# ATmega644 device description
Architecture: AVR8; Family: megaAVR
Registers are 8-bit, access not given, no defined reset value unless marked. A register's access mark holds for its fields unless they carry their own. Offsets are from the block's base; [hi:lo] are bit positions; {n}, {i} and the like mark numbered series.

## ADC — Analog-to-Digital Converter
Instances: ADC 0x00
0x78 ADC 16-bit — ADC Data Register Bytes
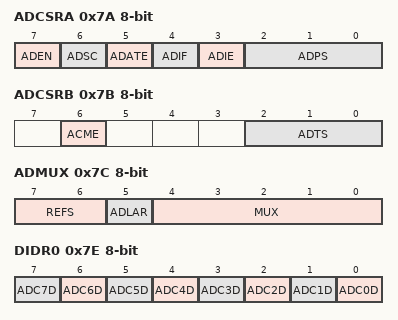
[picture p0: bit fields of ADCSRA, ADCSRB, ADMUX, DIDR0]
0x7A ADCSRA — The ADC Control and Status register A
  [7] ADEN — ADC Enable
  [6] ADSC — ADC Start Conversion
  [5] ADATE — ADC Auto Trigger Enable
  [4] ADIF — ADC Interrupt Flag
  [3] ADIE — ADC Interrupt Enable
  [2:0] ADPS — ADC Prescaler Select Bits
    0=2; 1=2; 2=4; 3=8; 4=16; 5=32; 6=64; 7=128
0x7B ADCSRB — The ADC Control and Status register B
  [6] ACME
  [2:0] ADTS — ADC Auto Trigger Source bits
    0=Free Running mode; 1=Analog Comparator; 2=External Interrupt Request 0; 3=Timer/Counter0 Compare Match A; 4=Timer/Counter0 Overflow; 5=Timer/Counter1 Compare Match B; 6=Timer/Counter1 Overflow; 7=Timer/Counter1 Capture Event
0x7C ADMUX — The ADC multiplexer Selection Register
  [7:6] REFS — Reference Selection Bits
    0=AREF, Internal Vref turned off; 1=AVCC with external capacitor at AREF pin; 2=Internal 1.1V Voltage Reference with external capacitor at AREF pin; 3=Internal 2.56V Voltage Reference with external capacitor at AREF pin
  [5] ADLAR — Left Adjust Result
  [4:0] MUX — Analog Channel and Gain Selection Bits
    {v}=ADC{v} (ADC Single Ended Input pin {v}) (v=0..7); 8=ADC0_ADC0_10X (ADC Differential Inputs Postive pin 0 Negative pin 0 10x Gain); 9=ADC1_ADC0_10X (ADC Differential Inputs Postive pin 1 Negative pin 0 10x Gain); 10=ADC0_ADC0_200x (ADC Differential Inputs Postive pin 0 Negative pin 0 200x Gain); 11=ADC1_ADC0_200X (ADC Differential Inputs Postive pin 1 Negative pin 0 200x Gain); 12=ADC2_ADC2_10X (ADC Differential Inputs Postive pin 2 Negative pin 2 10x Gain); 13=ADC3_ADC2_10X (ADC Differential Inputs Postive pin 3 Negative pin 2 10x Gain); 14=ADC2_ADC2_200X (ADC Differential Inputs Postive pin 2 Negative pin 2 200x Gain); 15=ADC3_ADC2_200X (ADC Differential Inputs Postive pin 3 Negative pin 2 200x Gain); {v}=ADC{v-16}_ADC1_1X (ADC Differential Inputs Postive pin {v-16} Negative pin 1 1x Gain) (v=16..23); {v}=ADC{v-24}_ADC2_1X (ADC Differential Inputs Postive pin {v-24} Negative pin 2 1x Gain) (v=24..29); 30=ADC_VBG (Internal Reference (VBG)); 31=ADC_GND (0V (GND))
0x7E DIDR0 — Digital Input Disable Register
  [n] ADC{n}D (n=0..7)

## TC1 (TC16 module) — Timer/Counter, 16-bit
Instances: TC1 0x00
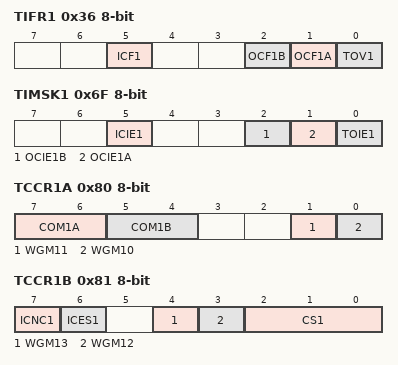
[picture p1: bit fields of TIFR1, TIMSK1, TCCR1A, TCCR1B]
0x36 TIFR1 — Timer/Counter Interrupt Flag register
  [5] ICF1 — Timer/Counter1 Input Capture Flag
  [2] OCF1B — Timer/Counter1 Output Compare B Match Flag
  [1] OCF1A — Timer/Counter1 Output Compare A Match Flag
  [0] TOV1 — Timer/Counter1 Overflow Flag
0x6F TIMSK1 — Timer/Counter1 Interrupt Mask Register
  [5] ICIE1 — Timer/Counter1 Input Capture Interrupt Enable
  [2] OCIE1B — Timer/Counter1 Output Compare B Match Interrupt Enable
  [1] OCIE1A — Timer/Counter1 Output Compare A Match Interrupt Enable
  [0] TOIE1 — Timer/Counter1 Overflow Interrupt Enable
0x80 TCCR1A — Timer/Counter1 Control Register A
  [7:6] COM1A — Compare Output Mode 1A, bits
  [5:4] COM1B — Compare Output Mode 1B, bits
  [1] WGM11 — Waveform Generation Mode
  [0] WGM10 — Waveform Generation Mode
0x81 TCCR1B — Timer/Counter1 Control Register B
  [7] ICNC1 — Input Capture 1 Noise Canceler
  [6] ICES1 — Input Capture 1 Edge Select
  [4] WGM13 (bit 2 of the value upward) — Waveform Generation Mode
  [3] WGM12 (bit 2 of the value upward) — Waveform Generation Mode
  [2:0] CS1 — Clock Select1 bits
    0=No Clock Source (Stopped); 1=Running, No Prescaling; 2=Running, CLK/8; 3=Running, CLK/64; 4=Running, CLK/256; 5=Running, CLK/1024; 6=Running, ExtClk Tx Falling Edge; 7=Running, ExtClk Tx Rising Edge
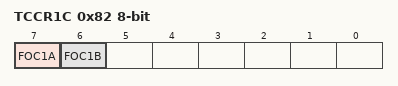
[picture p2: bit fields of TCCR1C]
0x82 TCCR1C — Timer/Counter1 Control Register C
  [7] FOC1A — Force Output Compare for Channel A
  [6] FOC1B — Force Output Compare for Channel B
0x84 TCNT1 16-bit — Timer/Counter1 Bytes
0x86 ICR1 16-bit — Timer/Counter1 Input Capture Register Bytes
0x88 OCR1A 16-bit — Timer/Counter1 Output Compare Register A Bytes
0x8A OCR1B 16-bit — Timer/Counter1 Output Compare Register B Bytes

## EEPROM
Instances: EEPROM 0x00
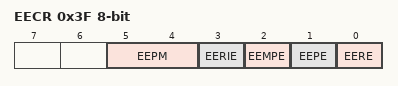
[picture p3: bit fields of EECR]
0x3F EECR — EEPROM Control Register
  [5:4] EEPM — EEPROM Programming Mode Bits
    0=Erase and Write in one operation; 1=Erase Only; 2=Write Only
  [3] EERIE — EEPROM Ready Interrupt Enable
  [2] EEMPE — EEPROM Master Write Enable
  [1] EEPE — EEPROM Write Enable
  [0] EERE — EEPROM Read Enable
0x40 EEDR — EEPROM Data Register
0x41 EEAR 16-bit bits used 11:0 — EEPROM Address Register Low Bytes

## TWI — Two Wire Serial Interface
Instances: TWI 0x00
0xB8 TWBR — TWI Bit Rate register
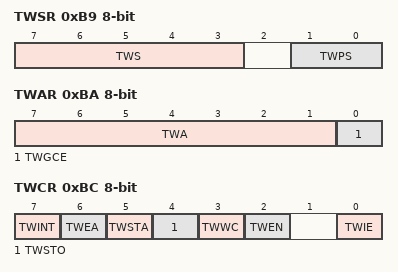
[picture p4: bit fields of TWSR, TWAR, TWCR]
0xB9 TWSR — TWI Status Register
  [7:3] TWS (bit 3 of the value upward) — TWI Status
  [1:0] TWPS — TWI Prescaler
    0=1; 1=4; 2=16; 3=64
0xBA TWAR — TWI (Slave) Address register
  [7:1] TWA — TWI (Slave) Address register Bits
  [0] TWGCE — TWI General Call Recognition Enable Bit
0xBB TWDR — TWI Data register
0xBC TWCR — TWI Control Register
  [7] TWINT — TWI Interrupt Flag
  [6] TWEA — TWI Enable Acknowledge Bit
  [5] TWSTA — TWI Start Condition Bit
  [4] TWSTO — TWI Stop Condition Bit
  [3] TWWC — TWI Write Collition Flag
  [2] TWEN — TWI Enable Bit
  [0] TWIE — TWI Interrupt Enable
0xBD TWAMR — TWI (Slave) Address Mask Register
  [7:1] TWAM

## SPI — Serial Peripheral Interface
Instances: SPI 0x00
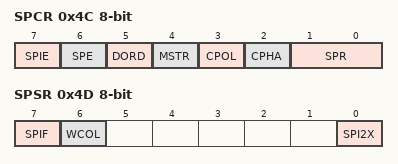
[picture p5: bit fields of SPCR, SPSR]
0x4C SPCR — SPI Control Register
  [7] SPIE — SPI Interrupt Enable
  [6] SPE — SPI Enable
  [5] DORD — Data Order
  [4] MSTR — Master/Slave Select
  [3] CPOL — Clock polarity
  [2] CPHA — Clock Phase
  [1:0] SPR — SPI Clock Rate Selects
    0=fosc/4; 1=fosc/16; 2=fosc/64; 3=fosc/128; 4=fosc/2; 5=fosc/8; 6=fosc/32; 7=fosc/64
0x4D SPSR — SPI Status Register
  [7] SPIF — SPI Interrupt Flag
  [6] WCOL — Write Collision Flag
  [0] SPI2X — Double SPI Speed Bit
0x4E SPDR — SPI Data Register

## CPU — CPU Registers
Instances: CPU 0x00
Parameters: CORE_VERSION=V2E
0x3E GPIOR0 — General Purpose IO Register 0
0x4A GPIOR1 — General Purpose IO Register 1
0x4B GPIOR2 — General Purpose IO Register 2
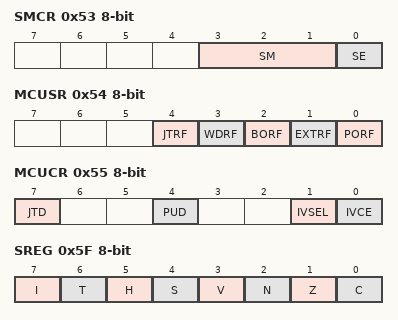
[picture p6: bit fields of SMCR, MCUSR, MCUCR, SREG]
0x53 SMCR — Sleep Mode Control Register
  [3:1] SM — Sleep Mode Select bits
    0=IDLE; 1=ADC (ADC Noise Reduction (If Available)); 2=PDOWN (Power Down); 3=PSAVE (Power Save); 6=STDBY (Standby); 7=ESTDBY (Extended Standby)
  [0] SE — Sleep Enable
0x54 MCUSR — MCU Status Register
  [4] JTRF — JTAG Reset Flag
  [3] WDRF — Watchdog Reset Flag
  [2] BORF — Brown-out Reset Flag
  [1] EXTRF — External Reset Flag
  [0] PORF — Power-on reset flag
0x55 MCUCR — MCU Control Register
  [7] JTD — JTAG Interface Disable
  [4] PUD — Pull-up disable
  [1] IVSEL — Interrupt Vector Select
  [0] IVCE — Interrupt Vector Change Enable
0x5D SP 16-bit bits used 12:0 — Stack Pointer
0x5F SREG — Status Register
  [7] I — Global Interrupt Enable
  [6] T — Bit Copy Storage
  [5] H — Half Carry Flag
  [4] S — Sign Bit
  [3] V — Two's Complement Overflow Flag
  [2] N — Negative Flag
  [1] Z — Zero Flag
  [0] C — Carry Flag
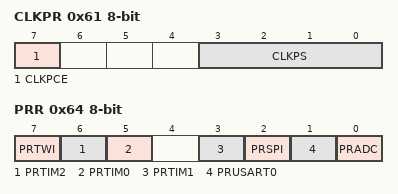
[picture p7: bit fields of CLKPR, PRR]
0x61 CLKPR
  [7] CLKPCE
  [3:0] CLKPS
    0=1; 1=2; 2=4; 3=8; 4=16; 5=32; 6=64; 7=128; 8=256
0x64 PRR — Power Reduction Register
  [7] PRTWI — Power Reduction TWI
  [6] PRTIM2 — Power Reduction Timer/Counter2
  [5] PRTIM0 — Power Reduction Timer/Counter0
  [3] PRTIM1 — Power Reduction Timer/Counter1
  [2] PRSPI — Power Reduction Serial Peripheral Interface
  [1] PRUSART0 — Power Reduction USART
  [0] PRADC — Power Reduction ADC
0x66 OSCCAL — Oscillator Calibration Value
  [7:0] OSCCAL — Oscillator Calibration
Value list OSCCAL_VALUE_ADDRESSES: 0=8_0_MHz
